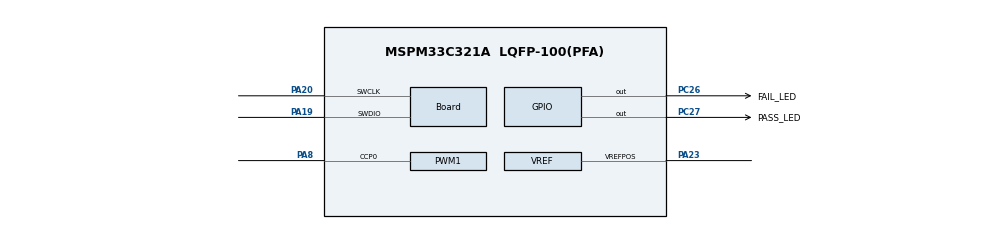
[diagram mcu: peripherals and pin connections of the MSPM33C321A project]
//@cliArgs --device "MSPM33C321A" --package "LQFP-100(PFA)" --part "Default"
//@v2CliArgs --device "MSPM33C321A" --package "LQFP-100(PFA)"
// @cliArgs --board /ti/boards/LP_MSPM33C321A --rtos nortos

/**
 * Import the modules used in this configuration.
 */
const Board         = scripting.addModule("/ti/driverlib/Board");
const COMP          = scripting.addModule("/ti/driverlib/COMP", {}, false);
const COMP1         = COMP.addInstance();
const GPIO          = scripting.addModule("/ti/driverlib/GPIO", {}, false);
const GPIO1         = GPIO.addInstance();
const PWM           = scripting.addModule("/ti/driverlib/PWM", {}, false);
const PWM1          = PWM.addInstance();
const VREF          = scripting.addModule("/ti/driverlib/VREF");
const ProjectConfig = scripting.addModule("/ti/project_config/ProjectConfig");

/**
 * Write custom configuration values to the imported modules.
 */
Board.peripheral.$assign          = "DEBUGSS";
Board.peripheral.swclkPin.$assign = "PA20";
Board.peripheral.swdioPin.$assign = "PA19";

COMP1.$name                          = "COMP";
COMP1.hysteresis                     = "DL_COMP_HYSTERESIS_30";
COMP1.vSource                        = "DL_COMP_REF_SOURCE_VDDA_DAC";
COMP1.enableOutputFilter             = true;
COMP1.selectOutputFilter             = "DL_COMP_FILTER_DELAY_1200";
COMP1.controlSelect                  = "DL_COMP_DAC_CONTROL_SW";
COMP1.channelEnable                  = ["POS"];
COMP1.terminalSelect                 = "DL_COMP_REF_TERMINAL_SELECT_NEG";
COMP1.peripheral.$assign             = "COMP0";
COMP1.peripheral.compPinPos0.$assign = "PA26";
COMP1.compPinPos0Config.$name        = "ti_driverlib_gpio_GPIOPinGeneric3";

GPIO1.$name                               = "GPIO_LEDS";
GPIO1.associatedPins.create(2);
GPIO1.associatedPins[0].$name             = "PASS_LED";
GPIO1.associatedPins[0].launchPadShortcut = "LED2GreenEn";
GPIO1.associatedPins[0].pin.$assign       = "PC27";
GPIO1.associatedPins[1].$name             = "FAIL_LED";
GPIO1.associatedPins[1].launchPadShortcut = "LED2RedEn";
GPIO1.associatedPins[1].pin.$assign       = "PC26";

PWM1.$name                      = "PWM_0";
PWM1.ccIndex                    = [0];
PWM1.clockPrescale              = 256;
PWM1.timerCount                 = 2000;
PWM1.faultHandlerEn             = true;
PWM1.faultSource                = ["3"];
PWM1.COMP0Sense                 = "SENSE_HIGH";
PWM1.faultInput                 = "FI_DEPENDENT";
PWM1.faultTimerCountEntry       = "FAULT_ENTRY_CTR_SUSP_COUNT";
PWM1.faultTimerCountExit        = "FAULT_EXIT_CTR_CVAE_ACTION";
PWM1.faultInputFilterEn         = true;
PWM1.faultChannel0BehaviorEntry = "HIGHZ";
PWM1.faultInputEn               = "FIEN_ENABLED";
PWM1.faultInputDetect           = true;
PWM1.PWM_CHANNEL_0.$name        = "ti_driverlib_pwm_PWMTimerCC0";
PWM1.PWM_CHANNEL_0.ccValue      = 500;
PWM1.ccp0PinConfig.$name        = "ti_driverlib_gpio_GPIOPinGeneric0";
PWM1.peripheral.$assign         = "TIMA0_0";
PWM1.peripheral.ccp0Pin.$assign = "PA8";

const SYSCTL              = scripting.addModule("/ti/driverlib/SYSCTL", {}, false);
SYSCTL.peripheral.$assign = "SYSCTL";

VREF.basicMode                     = "DL_VREF_ENABLE_ENABLE";
VREF.basicIntVolt                  = "DL_VREF_BUFCONFIG_OUTPUT_1_4V";
VREF.peripheral.$assign            = "VREF";
VREF.peripheral.vrefPosPin.$assign = "PA23";
VREF.vrefPosPinConfig.$name        = "ti_driverlib_gpio_GPIOPinGeneric2";

ProjectConfig.genLinker          = true;
ProjectConfig.genStartup         = true;
ProjectConfig.genOpts            = true;
ProjectConfig.genLibs            = true;
ProjectConfig.migrationCondition = true;
